AUTOSAR XML (schema 00044)
package /VAG/Services/BAP
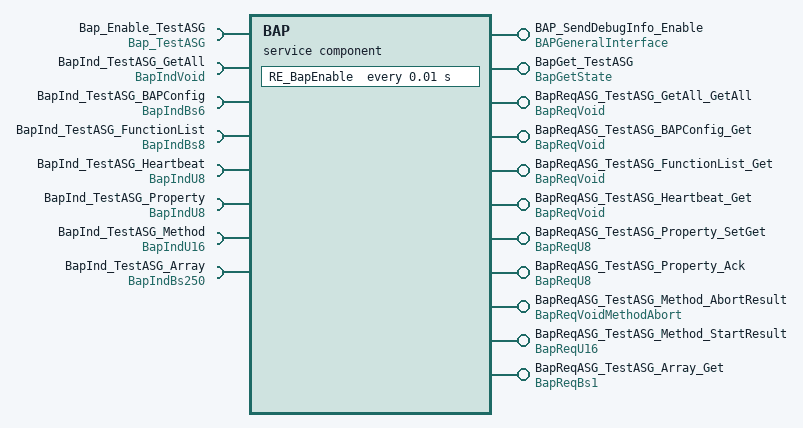
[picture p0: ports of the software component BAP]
  service sw component type BAP: category=SERVICE_COMPONENT
    provide port BAP_SendDebugInfo_Enable: server-com-spec{operation=BAP_SendDebugInfo_Enable, queue-length=1}, provided-interface=BAPGeneralInterface
    provide port BapGet_TestASG: server-com-spec{operation=State, queue-length=1}, provided-interface=BapGetState
    require port Bap_Enable_TestASG: nonqueued-receiver-com-spec{data-element=BapEnable, filter=data-filter-type=ALWAYS, init-value=constant-reference=C_Bool_FALSE}, required-interface=Bap_TestASG
    require port BapInd_TestASG_GetAll: required-com-specs=[BAP_IndVoid, BAP_IndError, BAP_Ack], required-interface=BapIndVoid
    provide port BapReqASG_TestASG_GetAll_GetAll: server-com-spec{operation=BAP_ReqVoid, queue-length=1}, provided-interface=BapReqVoid
    require port BapInd_TestASG_BAPConfig: required-com-specs=[BAP_IndBs, BAP_IndError, BAP_Ack], required-interface=BapIndBs6
    provide port BapReqASG_TestASG_BAPConfig_Get: server-com-spec{operation=BAP_ReqVoid, queue-length=1}, provided-interface=BapReqVoid
    require port BapInd_TestASG_FunctionList: required-com-specs=[BAP_IndBs, BAP_IndError, BAP_Ack], required-interface=BapIndBs8
    provide port BapReqASG_TestASG_FunctionList_Get: server-com-spec{operation=BAP_ReqVoid, queue-length=1}, provided-interface=BapReqVoid
    require port BapInd_TestASG_Heartbeat: required-com-specs=[BAP_IndU8, BAP_IndError, BAP_Ack], required-interface=BapIndU8
    provide port BapReqASG_TestASG_Heartbeat_Get: server-com-spec{operation=BAP_ReqVoid, queue-length=1}, provided-interface=BapReqVoid
    require port BapInd_TestASG_Property: required-com-specs=[BAP_IndU8, BAP_IndError, BAP_Ack], required-interface=BapIndU8
    provide port BapReqASG_TestASG_Property_SetGet: server-com-spec{operation=BAP_ReqU8, queue-length=1}, provided-interface=BapReqU8
    provide port BapReqASG_TestASG_Property_Ack: server-com-spec{operation=BAP_ReqU8, queue-length=1}, provided-interface=BapReqU8
    require port BapInd_TestASG_Method: required-com-specs=[BAP_IndU16, BAP_IndError, BAP_Ack], required-interface=BapIndU16
    provide port BapReqASG_TestASG_Method_AbortResult: server-com-spec{operation=BAP_ReqVoid, queue-length=1}, provided-interface=BapReqVoidMethodAbort
    provide port BapReqASG_TestASG_Method_StartResult: server-com-spec{operation=BAP_ReqU16, queue-length=1}, provided-interface=BapReqU16
    require port BapInd_TestASG_Array: required-com-specs=[BAP_IndBs, BAP_IndError, BAP_Ack], required-interface=BapIndBs250
    provide port BapReqASG_TestASG_Array_Get: server-com-spec{operation=BAP_ReqBs, queue-length=1}, provided-interface=BapReqBs1
    behavior IB_BAP
      timing event TE_RE_BapEnable: start-on-event=RE_BapEnable, period=0.01
      11 x operation invoked event:
        OIE_RE_BapSendDebugInfo_Enable_BAP_SendDebugInfo_Enable: start-on-event=RE_BapSendDebugInfo_Enable, operation=BAP_SendDebugInfo_Enable.BAP_SendDebugInfo_Enable
        OIE_RE_Bap_TestASG_State_BapGet_TestASG: start-on-event=RE_Bap_TestASG_State, operation=BapGet_TestASG.State
        OIE_RE_BapReqVoid_BapReqASG_TestASG_GetAll_GetAll: start-on-event=RE_BapReqVoid, operation=BapReqASG_TestASG_GetAll_GetAll.BAP_ReqVoid
        OIE_RE_BapReqVoid_BapReqASG_TestASG_BAPConfig_Get: start-on-event=RE_BapReqVoid, operation=BapReqASG_TestASG_BAPConfig_Get.BAP_ReqVoid
        OIE_RE_BapReqVoid_BapReqASG_TestASG_FunctionList_Get: start-on-event=RE_BapReqVoid, operation=BapReqASG_TestASG_FunctionList_Get.BAP_ReqVoid
        OIE_RE_BapReqVoid_BapReqASG_TestASG_Heartbeat_Get: start-on-event=RE_BapReqVoid, operation=BapReqASG_TestASG_Heartbeat_Get.BAP_ReqVoid
        OIE_RE_BapReqU8_BapReqASG_TestASG_Property_SetGet: start-on-event=RE_BapReqU8, operation=BapReqASG_TestASG_Property_SetGet.BAP_ReqU8
        OIE_RE_BapReqU8_BapReqASG_TestASG_Property_Ack: start-on-event=RE_BapReqU8, operation=BapReqASG_TestASG_Property_Ack.BAP_ReqU8
        OIE_RE_BapReqVoid_BapReqASG_TestASG_Method_AbortResult: start-on-event=RE_BapReqVoid, operation=BapReqASG_TestASG_Method_AbortResult.BAP_ReqVoid
        OIE_RE_BapReqU16_BapReqASG_TestASG_Method_StartResult: start-on-event=RE_BapReqU16, operation=BapReqASG_TestASG_Method_StartResult.BAP_ReqU16
        OIE_RE_BapReqBs_BapReqASG_TestASG_Array_Get: start-on-event=RE_BapReqBs1, operation=BapReqASG_TestASG_Array_Get.BAP_ReqBs
      port-api-options:
        enable-take-address=false, indirect-api=false, port=Bap_Enable_TestASG
        enable-take-address=false, indirect-api=false, port=BapInd_TestASG_GetAll
        enable-take-address=false, indirect-api=false, port=BapInd_TestASG_BAPConfig
        enable-take-address=false, indirect-api=false, port=BapInd_TestASG_FunctionList
        enable-take-address=false, indirect-api=false, port=BapInd_TestASG_Heartbeat
        enable-take-address=false, indirect-api=false, port=BapInd_TestASG_Property
        enable-take-address=false, indirect-api=false, port=BapInd_TestASG_Method
        enable-take-address=false, indirect-api=false, port=BapInd_TestASG_Array
        enable-take-address=false, indirect-api=false, port=BAP_SendDebugInfo_Enable
        enable-take-address=false, indirect-api=false, port=BapGet_TestASG
        {enable-take-address=false, indirect-api=false, port-arg-values=[{value=PortArgPropFSG_LsgID_TestASG_GetAll_GetAll:1, value-type=lsgId_t}, {value=PortArgPropFSG_FctID_TestASG_GetAll_GetAll:1, value-type=fctId_t}, {value=PortArgPropFSG_OpCode_TestASG_GetAll_GetAll:2, value-type=BapReq_et}], port=BapReqASG_TestASG_GetAll_GetAll}
        {enable-take-address=false, indirect-api=false, port-arg-values=[{value=PortArgPropFSG_LsgID_TestASG_BAPConfig_Get:1, value-type=lsgId_t}, {value=PortArgPropFSG_FctID_TestASG_BAPConfig_Get:2, value-type=fctId_t}, {value=PortArgPropFSG_OpCode_TestASG_BAPConfig_Get:2, value-type=BapReq_et}], port=BapReqASG_TestASG_BAPConfig_Get}
        {enable-take-address=false, indirect-api=false, port-arg-values=[{value=PortArgPropFSG_LsgID_TestASG_FunctionList_Get:1, value-type=lsgId_t}, {value=PortArgPropFSG_FctID_TestASG_FunctionList_Get:3, value-type=fctId_t}, {value=PortArgPropFSG_OpCode_TestASG_FunctionList_Get:2, value-type=BapReq_et}], port=BapReqASG_TestASG_FunctionList_Get}
        {enable-take-address=false, indirect-api=false, port-arg-values=[{value=PortArgPropFSG_LsgID_TestASG_Heartbeat_Get:1, value-type=lsgId_t}, {value=PortArgPropFSG_FctID_TestASG_Heartbeat_Get:4, value-type=fctId_t}, {value=PortArgPropFSG_OpCode_TestASG_Heartbeat_Get:2, value-type=BapReq_et}], port=BapReqASG_TestASG_Heartbeat_Get}
        {enable-take-address=false, indirect-api=false, port-arg-values=[{value=PortArgPropFSG_LsgID_TestASG_Property_SetGet:1, value-type=lsgId_t}, {value=PortArgPropFSG_FctID_TestASG_Property_SetGet:16, value-type=fctId_t}, {value=PortArgPropFSG_OpCode_TestASG_Property_SetGet:0, value-type=BapReq_et}], port=BapReqASG_TestASG_Property_SetGet}
        {enable-take-address=false, indirect-api=false, port-arg-values=[{value=PortArgPropFSG_LsgID_TestASG_Property_Ack:1, value-type=lsgId_t}, {value=PortArgPropFSG_FctID_TestASG_Property_Ack:16, value-type=fctId_t}, {value=PortArgPropFSG_OpCode_TestASG_Property_Ack:11, value-type=BapReq_et}], port=BapReqASG_TestASG_Property_Ack}
        {enable-take-address=false, indirect-api=false, port-arg-values=[{value=PortArgPropFSG_LsgID_TestASG_Method_AbortResult:1, value-type=lsgId_t}, {value=PortArgPropFSG_FctID_TestASG_Method_AbortResult:20, value-type=fctId_t}, {value=PortArgPropFSG_OpCode_TestASG_Method_AbortResult:7, value-type=BapReq_et}], port=BapReqASG_TestASG_Method_AbortResult}
        {enable-take-address=false, indirect-api=false, port-arg-values=[{value=PortArgPropFSG_LsgID_TestASG_Method_StartResult:1, value-type=lsgId_t}, {value=PortArgPropFSG_FctID_TestASG_Method_StartResult:20, value-type=fctId_t}, {value=PortArgPropFSG_OpCode_TestASG_Method_StartResult:6, value-type=BapReq_et}], port=BapReqASG_TestASG_Method_StartResult}
        {enable-take-address=false, indirect-api=false, port-arg-values=[{value=PortArgPropFSG_LsgID_TestASG_Array_Get:1, value-type=lsgId_t}, {value=PortArgPropFSG_FctID_TestASG_Array_Get:30, value-type=fctId_t}, {value=PortArgPropFSG_OpCode_TestASG_Array_Get:2, value-type=BapReq_et}], port=BapReqASG_TestASG_Array_Get}
      8 x runnable:
        RE_BapEnable: symbol=Bap_Enable
          data-receive-point-by-arguments:
            access DRP_TestASG_BapEnable: accessed-variable=Bap_Enable_TestASG.BapEnable
        RE_BapDummy: symbol=BapDummy
          21 x sync call, all with timeout=0:
            SCP_BapInd_TestASG_GetAll_BAP_IndVoid: operation=BapInd_TestASG_GetAll.BAP_IndVoid
            SCP_BapInd_TestASG_GetAll_BAP_IndError: operation=BapInd_TestASG_GetAll.BAP_IndError
            SCP_BapInd_TestASG_GetAll_BAP_Ack: operation=BapInd_TestASG_GetAll.BAP_Ack
            SCP_BapInd_TestASG_BAPConfig_BAP_IndBs: operation=BapInd_TestASG_BAPConfig.BAP_IndBs
            SCP_BapInd_TestASG_BAPConfig_BAP_IndError: operation=BapInd_TestASG_BAPConfig.BAP_IndError
            SCP_BapInd_TestASG_BAPConfig_BAP_Ack: operation=BapInd_TestASG_BAPConfig.BAP_Ack
            SCP_BapInd_TestASG_FunctionList_BAP_IndBs: operation=BapInd_TestASG_FunctionList.BAP_IndBs
            SCP_BapInd_TestASG_FunctionList_BAP_IndError: operation=BapInd_TestASG_FunctionList.BAP_IndError
            SCP_BapInd_TestASG_FunctionList_BAP_Ack: operation=BapInd_TestASG_FunctionList.BAP_Ack
            SCP_BapInd_TestASG_Heartbeat_BAP_IndU8: operation=BapInd_TestASG_Heartbeat.BAP_IndU8
            SCP_BapInd_TestASG_Heartbeat_BAP_IndError: operation=BapInd_TestASG_Heartbeat.BAP_IndError
            SCP_BapInd_TestASG_Heartbeat_BAP_Ack: operation=BapInd_TestASG_Heartbeat.BAP_Ack
            SCP_BapInd_TestASG_Property_BAP_IndU8: operation=BapInd_TestASG_Property.BAP_IndU8
            SCP_BapInd_TestASG_Property_BAP_IndError: operation=BapInd_TestASG_Property.BAP_IndError
            SCP_BapInd_TestASG_Property_BAP_Ack: operation=BapInd_TestASG_Property.BAP_Ack
            SCP_BapInd_TestASG_Method_BAP_IndU16: operation=BapInd_TestASG_Method.BAP_IndU16
            SCP_BapInd_TestASG_Method_BAP_IndError: operation=BapInd_TestASG_Method.BAP_IndError
            SCP_BapInd_TestASG_Method_BAP_Ack: operation=BapInd_TestASG_Method.BAP_Ack
            SCP_BapInd_TestASG_Array_BAP_IndBs: operation=BapInd_TestASG_Array.BAP_IndBs
            SCP_BapInd_TestASG_Array_BAP_IndError: operation=BapInd_TestASG_Array.BAP_IndError
            SCP_BapInd_TestASG_Array_BAP_Ack: operation=BapInd_TestASG_Array.BAP_Ack
        RE_BapSendDebugInfo_Enable: can-be-invoked-concurrently=true, symbol=BAP_ASR_SendDebugInfo_Enable
        RE_Bap_TestASG_State: can-be-invoked-concurrently=true, symbol=Provide_Bap_TestASG_State
        RE_BapReqVoid: can-be-invoked-concurrently=true, symbol=BAP_ASR_ReqVoid
        RE_BapReqU8: can-be-invoked-concurrently=true, symbol=BAP_ASR_ReqU8
        RE_BapReqU16: can-be-invoked-concurrently=true, symbol=BAP_ASR_ReqU16
        RE_BapReqBs1: can-be-invoked-concurrently=true, symbol=BAP_ASR_ReqBs1
